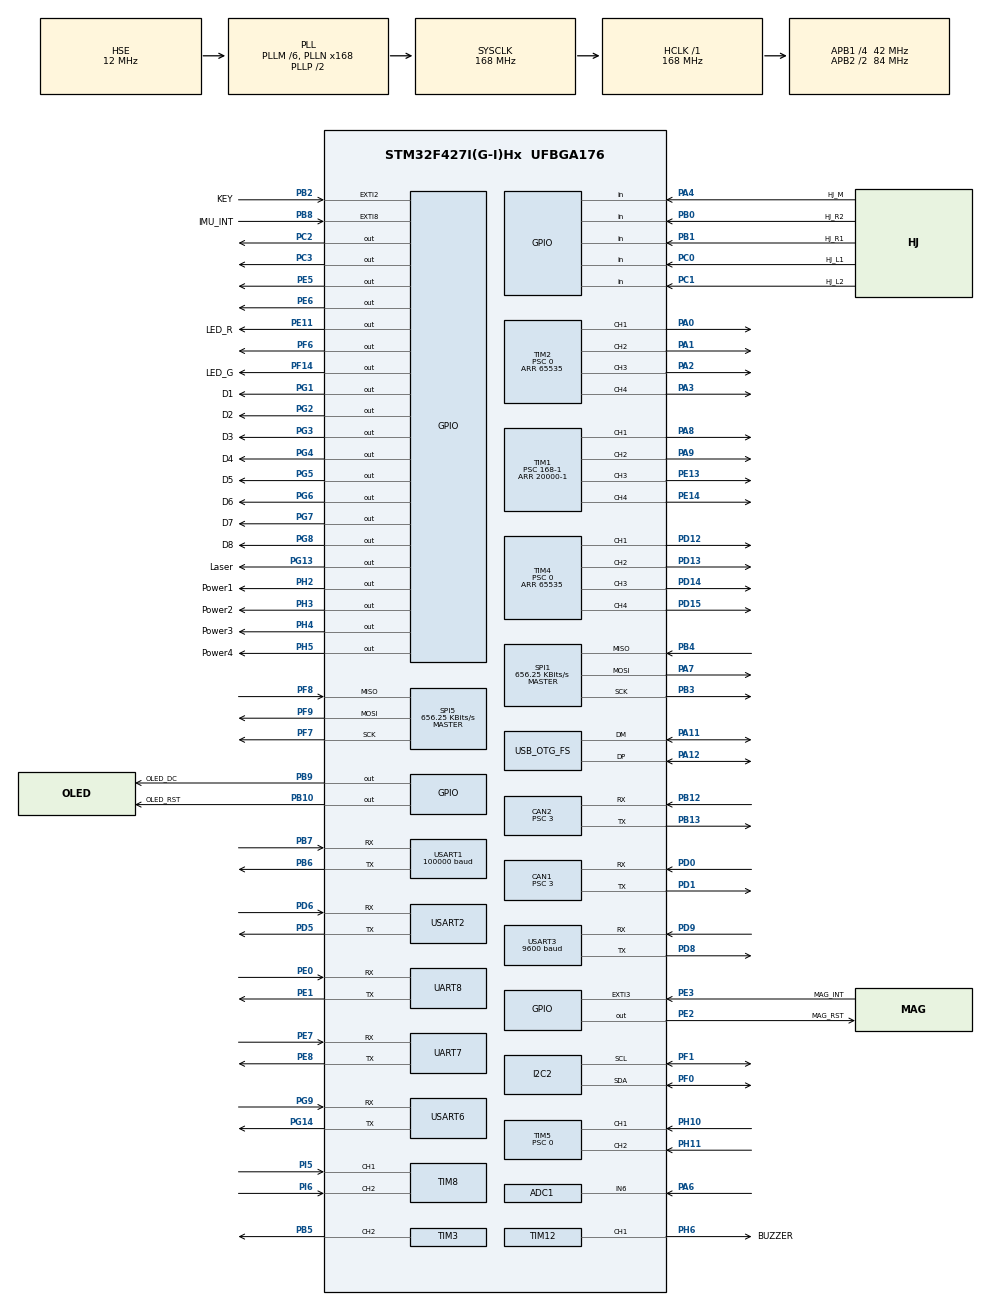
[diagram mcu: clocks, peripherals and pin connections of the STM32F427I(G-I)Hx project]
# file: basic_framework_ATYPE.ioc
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ADC1.Channel-0\#ChannelRegularConversion=ADC_CHANNEL_6
ADC1.NbrOfConversionFlag=1
ADC1.Rank-0\#ChannelRegularConversion=1
ADC1.SamplingTime-0\#ChannelRegularConversion=ADC_SAMPLETIME_3CYCLES
ADC1.master=1
CAN1.BS1=CAN_BS1_10TQ
CAN1.BS2=CAN_BS2_3TQ
CAN1.CalculateBaudRate=1000000
CAN1.CalculateTimeBit=1000
CAN1.CalculateTimeQuantum=71.42857142857143
CAN1.ABOM=ENABLE
CAN1.NART=ENABLE
CAN1.Prescaler=3
CAN1.TXFP=ENABLE
CAN2.BS1=CAN_BS1_10TQ
CAN2.BS2=CAN_BS2_3TQ
CAN2.CalculateBaudRate=1000000
CAN2.CalculateTimeBit=1000
CAN2.CalculateTimeQuantum=71.42857142857143
CAN2.ABOM=ENABLE
CAN2.NART=ENABLE
CAN2.Prescaler=3
CAN2.TXFP=ENABLE
Dma.Request0=USART1_RX
Dma.Request1=USART3_RX
Dma.Request2=USART3_TX
Dma.Request3=USART6_RX
Dma.Request4=USART6_TX
Dma.Request5=UART7_RX
Dma.Request6=UART8_RX
Dma.Request7=UART8_TX
Dma.Request8=USART2_RX
Dma.UART7_RX.5.Direction=DMA_PERIPH_TO_MEMORY
Dma.UART7_RX.5.FIFOMode=DMA_FIFOMODE_ENABLE
Dma.UART7_RX.5.FIFOThreshold=DMA_FIFO_THRESHOLD_FULL
Dma.UART7_RX.5.Instance=DMA1_Stream3
Dma.UART7_RX.5.MemBurst=DMA_MBURST_SINGLE
Dma.UART7_RX.5.MemDataAlignment=DMA_MDATAALIGN_BYTE
Dma.UART7_RX.5.MemInc=DMA_MINC_ENABLE
Dma.UART7_RX.5.Mode=DMA_NORMAL
Dma.UART7_RX.5.PeriphBurst=DMA_PBURST_SINGLE
Dma.UART7_RX.5.PeriphDataAlignment=DMA_PDATAALIGN_BYTE
Dma.UART7_RX.5.PeriphInc=DMA_PINC_DISABLE
Dma.UART7_RX.5.Priority=DMA_PRIORITY_LOW
Dma.UART8_RX.6.Direction=DMA_PERIPH_TO_MEMORY
Dma.UART8_RX.6.FIFOMode=DMA_FIFOMODE_ENABLE
Dma.UART8_RX.6.FIFOThreshold=DMA_FIFO_THRESHOLD_FULL
Dma.UART8_RX.6.Instance=DMA1_Stream6
Dma.UART8_RX.6.MemBurst=DMA_MBURST_SINGLE
Dma.UART8_RX.6.MemDataAlignment=DMA_MDATAALIGN_BYTE
Dma.UART8_RX.6.MemInc=DMA_MINC_ENABLE
Dma.UART8_RX.6.Mode=DMA_NORMAL
Dma.UART8_RX.6.PeriphBurst=DMA_PBURST_SINGLE
Dma.UART8_RX.6.PeriphDataAlignment=DMA_PDATAALIGN_BYTE
Dma.UART8_RX.6.PeriphInc=DMA_PINC_DISABLE
Dma.UART8_RX.6.Priority=DMA_PRIORITY_LOW
Dma.UART8_TX.7.Direction=DMA_MEMORY_TO_PERIPH
Dma.UART8_TX.7.FIFOMode=DMA_FIFOMODE_DISABLE
Dma.UART8_TX.7.Instance=DMA1_Stream0
Dma.UART8_TX.7.MemDataAlignment=DMA_MDATAALIGN_BYTE
Dma.UART8_TX.7.MemInc=DMA_MINC_ENABLE
Dma.UART8_TX.7.Mode=DMA_NORMAL
Dma.UART8_TX.7.PeriphDataAlignment=DMA_PDATAALIGN_BYTE
Dma.UART8_TX.7.PeriphInc=DMA_PINC_DISABLE
Dma.UART8_TX.7.Priority=DMA_PRIORITY_LOW
Dma.USART1_RX.0.Direction=DMA_PERIPH_TO_MEMORY
Dma.USART1_RX.0.FIFOMode=DMA_FIFOMODE_DISABLE
Dma.USART1_RX.0.Instance=DMA2_Stream2
Dma.USART1_RX.0.MemDataAlignment=DMA_MDATAALIGN_BYTE
Dma.USART1_RX.0.MemInc=DMA_MINC_ENABLE
Dma.USART1_RX.0.Mode=DMA_NORMAL
Dma.USART1_RX.0.PeriphDataAlignment=DMA_PDATAALIGN_BYTE
Dma.USART1_RX.0.PeriphInc=DMA_PINC_DISABLE
Dma.USART1_RX.0.Priority=DMA_PRIORITY_LOW
Dma.USART2_RX.8.Direction=DMA_PERIPH_TO_MEMORY
Dma.USART2_RX.8.FIFOMode=DMA_FIFOMODE_DISABLE
Dma.USART2_RX.8.Instance=DMA1_Stream5
Dma.USART2_RX.8.MemDataAlignment=DMA_MDATAALIGN_BYTE
Dma.USART2_RX.8.MemInc=DMA_MINC_ENABLE
Dma.USART2_RX.8.Mode=DMA_NORMAL
Dma.USART2_RX.8.PeriphDataAlignment=DMA_PDATAALIGN_BYTE
Dma.USART2_RX.8.PeriphInc=DMA_PINC_DISABLE
Dma.USART2_RX.8.Priority=DMA_PRIORITY_HIGH
Dma.USART3_RX.1.Direction=DMA_PERIPH_TO_MEMORY
Dma.USART3_RX.1.FIFOMode=DMA_FIFOMODE_DISABLE
Dma.USART3_RX.1.Instance=DMA1_Stream1
Dma.USART3_RX.1.MemDataAlignment=DMA_MDATAALIGN_BYTE
Dma.USART3_RX.1.MemInc=DMA_MINC_ENABLE
Dma.USART3_RX.1.Mode=DMA_NORMAL
Dma.USART3_RX.1.PeriphDataAlignment=DMA_PDATAALIGN_BYTE
Dma.USART3_RX.1.PeriphInc=DMA_PINC_DISABLE
Dma.USART3_RX.1.Priority=DMA_PRIORITY_VERY_HIGH
Dma.USART3_TX.2.Direction=DMA_MEMORY_TO_PERIPH
Dma.USART3_TX.2.FIFOMode=DMA_FIFOMODE_DISABLE
Dma.USART3_TX.2.Instance=DMA1_Stream4
Dma.USART3_TX.2.MemDataAlignment=DMA_MDATAALIGN_BYTE
Dma.USART3_TX.2.MemInc=DMA_MINC_ENABLE
Dma.USART3_TX.2.Mode=DMA_NORMAL
Dma.USART3_TX.2.PeriphDataAlignment=DMA_PDATAALIGN_BYTE
Dma.USART3_TX.2.PeriphInc=DMA_PINC_DISABLE
Dma.USART3_TX.2.Priority=DMA_PRIORITY_VERY_HIGH
Dma.USART6_RX.3.Direction=DMA_PERIPH_TO_MEMORY
Dma.USART6_RX.3.FIFOMode=DMA_FIFOMODE_DISABLE
Dma.USART6_RX.3.Instance=DMA2_Stream1
Dma.USART6_RX.3.MemDataAlignment=DMA_MDATAALIGN_BYTE
Dma.USART6_RX.3.MemInc=DMA_MINC_ENABLE
Dma.USART6_RX.3.Mode=DMA_NORMAL
Dma.USART6_RX.3.PeriphDataAlignment=DMA_PDATAALIGN_BYTE
Dma.USART6_RX.3.PeriphInc=DMA_PINC_DISABLE
Dma.USART6_RX.3.Priority=DMA_PRIORITY_HIGH
Dma.USART6_TX.4.Direction=DMA_MEMORY_TO_PERIPH
Dma.USART6_TX.4.FIFOMode=DMA_FIFOMODE_DISABLE
Dma.USART6_TX.4.Instance=DMA2_Stream6
Dma.USART6_TX.4.MemDataAlignment=DMA_MDATAALIGN_BYTE
Dma.USART6_TX.4.MemInc=DMA_MINC_ENABLE
Dma.USART6_TX.4.Mode=DMA_NORMAL
Dma.USART6_TX.4.PeriphDataAlignment=DMA_PDATAALIGN_BYTE
Dma.USART6_TX.4.PeriphInc=DMA_PINC_DISABLE
Dma.USART6_TX.4.Priority=DMA_PRIORITY_HIGH
FREERTOS.INCLUDE_vTaskDelayUntil=1
FREERTOS.Tasks01=defaultTask,0,128,StartDefaultTask,Default,NULL,Dynamic,NULL,NULL
FREERTOS.configENABLE_FPU=1
FREERTOS.configMAX_TASK_NAME_LEN=32
FREERTOS.configTOTAL_HEAP_SIZE=30000
Mcu.Family=STM32F4
Mcu.Name=STM32F427I(G-I)Hx
Mcu.Package=UFBGA176
NVIC.CAN1_RX0_IRQn=true\:5\:0\:false\:false\:true\:true\:true\:true\:true
NVIC.CAN1_RX1_IRQn=true\:5\:0\:false\:false\:true\:true\:true\:true\:true
NVIC.CAN2_RX0_IRQn=true\:5\:0\:false\:false\:true\:true\:true\:true\:true
NVIC.CAN2_RX1_IRQn=true\:5\:0\:false\:false\:true\:true\:true\:true\:true
NVIC.DMA1_Stream0_IRQn=true\:5\:0\:false\:false\:true\:true\:false\:true\:true
NVIC.DMA1_Stream1_IRQn=true\:5\:0\:false\:false\:true\:true\:false\:true\:true
NVIC.DMA1_Stream3_IRQn=true\:5\:0\:false\:false\:true\:true\:false\:true\:true
NVIC.DMA1_Stream4_IRQn=true\:5\:0\:false\:false\:true\:false\:false\:true\:true
NVIC.DMA1_Stream5_IRQn=true\:5\:0\:false\:false\:true\:true\:false\:true\:true
NVIC.DMA1_Stream6_IRQn=true\:5\:0\:false\:false\:true\:true\:false\:true\:true
NVIC.DMA2_Stream1_IRQn=true\:5\:0\:false\:false\:true\:true\:false\:true\:true
NVIC.DMA2_Stream2_IRQn=true\:5\:0\:false\:false\:true\:true\:false\:true\:true
NVIC.DMA2_Stream6_IRQn=true\:5\:0\:false\:false\:true\:true\:false\:true\:true
NVIC.EXTI2_IRQn=true\:5\:0\:false\:false\:true\:true\:true\:true\:true
NVIC.OTG_FS_IRQn=true\:5\:0\:false\:false\:true\:true\:false\:true\:true
NVIC.PriorityGroup=NVIC_PRIORITYGROUP_4
NVIC.SPI5_IRQn=true\:5\:0\:false\:false\:true\:true\:true\:true\:true
NVIC.TIM8_TRG_COM_TIM14_IRQn=true\:15\:0\:false\:false\:true\:false\:false\:true\:true
NVIC.TimeBase=TIM8_TRG_COM_TIM14_IRQn
NVIC.TimeBaseIP=TIM14
NVIC.UART7_IRQn=true\:5\:0\:false\:false\:true\:true\:true\:true\:true
NVIC.UART8_IRQn=true\:5\:0\:false\:false\:true\:true\:true\:true\:true
NVIC.USART1_IRQn=true\:5\:0\:false\:false\:true\:true\:true\:true\:true
NVIC.USART2_IRQn=true\:5\:0\:false\:false\:true\:true\:true\:true\:true
NVIC.USART3_IRQn=true\:5\:0\:false\:false\:true\:true\:true\:true\:true
NVIC.USART6_IRQn=true\:5\:0\:false\:false\:true\:true\:true\:true\:true
PA0/WKUP.Signal=S_TIM2_CH1_ETR
PA1.Signal=S_TIM2_CH2
PA10.Signal=USB_OTG_FS_ID
PA11.Mode=Device_Only
PA11.Signal=USB_OTG_FS_DM
PA12.Mode=Device_Only
PA12.Signal=USB_OTG_FS_DP
PA13.Mode=Serial_Wire
PA13.Signal=SYS_JTMS-SWDIO
PA14.Mode=Serial_Wire
PA14.Signal=SYS_JTCK-SWCLK
PA2.Signal=S_TIM2_CH3
PA3.Signal=S_TIM2_CH4
PA4.GPIO_Label=HJ_M
PA4.Signal=GPIO_Input
PA6.Signal=ADCx_IN6
PA7.Mode=Full_Duplex_Master
PA7.Signal=SPI1_MOSI
PA8.Signal=S_TIM1_CH1
PA9.Signal=S_TIM1_CH2
PB0.GPIO_Label=HJ_R2
PB0.Signal=GPIO_Input
PB1.GPIO_Label=HJ_R1
PB1.Signal=GPIO_Input
PB10.GPIO_Label=OLED_RST
PB10.Signal=GPIO_Output
PB12.Mode=CAN_Activate
PB12.Signal=CAN2_RX
PB13.Mode=CAN_Activate
PB13.Signal=CAN2_TX
PB2/BOOT1.GPIO_Label=KEY
PB2/BOOT1.GPIO_ModeDefaultEXTI=GPIO_MODE_IT_RISING
PB2/BOOT1.GPIO_PuPd=GPIO_PULLDOWN
PB2/BOOT1.Signal=GPXTI2
PB3.Mode=Full_Duplex_Master
PB3.Signal=SPI1_SCK
PB4.Mode=Full_Duplex_Master
PB4.Signal=SPI1_MISO
PB5.Signal=S_TIM3_CH2
PB6.Mode=Asynchronous
PB6.Signal=USART1_TX
PB7.Mode=Asynchronous
PB7.Signal=USART1_RX
PB8.GPIO_Label=IMU_INT
PB8.Signal=GPXTI8
PB9.GPIO_Label=OLED_DC
PB9.Signal=GPIO_Output
PC0.GPIO_Label=HJ_L1
PC0.Signal=GPIO_Input
PC1.GPIO_Label=HJ_L2
PC1.GPIO_PuPd=GPIO_NOPULL
PC1.Signal=GPIO_Input
PC2.GPIO_Speed=GPIO_SPEED_FREQ_HIGH
PC2.Signal=GPIO_Output
PC3.GPIO_Speed=GPIO_SPEED_FREQ_HIGH
PC3.Signal=GPIO_Output
PD0.Mode=CAN_Activate
PD0.Signal=CAN1_RX
PD1.Mode=CAN_Activate
PD1.Signal=CAN1_TX
PD12.Signal=S_TIM4_CH1
PD13.Signal=S_TIM4_CH2
PD14.Signal=S_TIM4_CH3
PD15.Signal=S_TIM4_CH4
PD5.Mode=Asynchronous
PD5.Signal=USART2_TX
PD6.Mode=Asynchronous
PD6.Signal=USART2_RX
PD8.Mode=Asynchronous
PD8.Signal=USART3_TX
PD9.Mode=Asynchronous
PD9.Signal=USART3_RX
PE0.Mode=Asynchronous
PE0.Signal=UART8_RX
PE1.Mode=Asynchronous
PE1.Signal=UART8_TX
PE11.GPIO_Label=LED_R
PE11.Signal=GPIO_Output
PE13.Signal=S_TIM1_CH3
PE14.Signal=S_TIM1_CH4
PE2.GPIO_Label=MAG_RST
PE2.Signal=GPIO_Output
PE3.GPIO_Label=MAG_INT
PE3.Signal=GPXTI3
PE5.GPIO_Speed=GPIO_SPEED_FREQ_HIGH
PE5.Signal=GPIO_Output
PE6.GPIO_Speed=GPIO_SPEED_FREQ_HIGH
PE6.Signal=GPIO_Output
PE7.Mode=Asynchronous
PE7.Signal=UART7_RX
PE8.Mode=Asynchronous
PE8.Signal=UART7_TX
PF0.Mode=I2C
PF0.Signal=I2C2_SDA
PF1.Mode=I2C
PF1.Signal=I2C2_SCL
PF14.GPIO_Label=LED_G
PF14.Signal=GPIO_Output
PF6.Signal=GPIO_Output
PF7.Mode=Full_Duplex_Master
PF7.Signal=SPI5_SCK
PF8.Mode=Full_Duplex_Master
PF8.Signal=SPI5_MISO
PF9.Mode=Full_Duplex_Master
PF9.Signal=SPI5_MOSI
PG1.GPIO_Label=D1
PG1.Signal=GPIO_Output
PG13.GPIO_Label=Laser
PG13.GPIO_PuPd=GPIO_PULLUP
PG13.Signal=GPIO_Output
PG14.Mode=Asynchronous
PG14.Signal=USART6_TX
PG2.GPIO_Label=D2
PG2.Signal=GPIO_Output
PG3.GPIO_Label=D3
PG3.Signal=GPIO_Output
PG4.GPIO_Label=D4
PG4.Signal=GPIO_Output
PG5.GPIO_Label=D5
PG5.Signal=GPIO_Output
PG6.GPIO_Label=D6
PG6.Signal=GPIO_Output
PG7.GPIO_Label=D7
PG7.Signal=GPIO_Output
PG8.GPIO_Label=D8
PG8.Signal=GPIO_Output
PG9.Mode=Asynchronous
PG9.Signal=USART6_RX
PH0/OSC_IN.Mode=HSE-External-Oscillator
PH0/OSC_IN.Signal=RCC_OSC_IN
PH1/OSC_OUT.Mode=HSE-External-Oscillator
PH1/OSC_OUT.Signal=RCC_OSC_OUT
PH10.Signal=S_TIM5_CH1
PH11.Signal=S_TIM5_CH2
PH2.GPIO_Label=Power1
PH2.GPIO_PuPd=GPIO_PULLDOWN
PH2.Signal=GPIO_Output
PH3.GPIO_Label=Power2
PH3.GPIO_PuPd=GPIO_PULLDOWN
PH3.Signal=GPIO_Output
PH4.GPIO_Label=Power3
PH4.GPIO_PuPd=GPIO_PULLDOWN
PH4.Signal=GPIO_Output
PH5.GPIO_Label=Power4
PH5.GPIO_PuPd=GPIO_PULLDOWN
PH5.Signal=GPIO_Output
PH6.GPIO_Label=BUZZER
PH6.GPIO_PuPd=GPIO_PULLUP
PH6.GPIO_Speed=GPIO_SPEED_FREQ_VERY_HIGH
PH6.Signal=S_TIM12_CH1
PI5.Signal=S_TIM8_CH1
PI6.Signal=S_TIM8_CH2
ProjectManager.HeapSize=0x4000
ProjectManager.StackSize=0x4000
ProjectManager.TargetToolchain=CMake
RCC.48MHZClocksFreq_Value=48000000
RCC.AHBFreq_Value=168000000
RCC.APB1CLKDivider=RCC_HCLK_DIV4
RCC.APB1Freq_Value=42000000
RCC.APB1TimFreq_Value=84000000
RCC.APB2CLKDivider=RCC_HCLK_DIV2
RCC.APB2Freq_Value=84000000
RCC.APB2TimFreq_Value=168000000
RCC.CortexFreq_Value=168000000
RCC.HCLKFreq_Value=168000000
RCC.HSE_VALUE=12000000
RCC.HSI_VALUE=16000000
RCC.LSE_VALUE=32768
RCC.PLLM=6
RCC.PLLN=168
RCC.PLLQ=7
RCC.SYSCLKFreq_VALUE=168000000
RCC.SYSCLKSource=RCC_SYSCLKSOURCE_PLLCLK
RCC.VCOOutputFreq_Value=336000000
RTC.AsynchPrediv=124
RTC.SynchPrediv=3199
SH.ADCx_IN6.0=ADC1_IN6,IN6
SH.S_TIM12_CH1.0=TIM12_CH1,PWM Generation1 CH1
SH.S_TIM1_CH1.0=TIM1_CH1,PWM Generation1 CH1
SH.S_TIM1_CH2.0=TIM1_CH2,PWM Generation2 CH2
SH.S_TIM1_CH3.0=TIM1_CH3,PWM Generation3 CH3
SH.S_TIM1_CH4.0=TIM1_CH4,PWM Generation4 CH4
SH.S_TIM2_CH1_ETR.0=TIM2_CH1,PWM Generation1 CH1
SH.S_TIM2_CH2.0=TIM2_CH2,PWM Generation2 CH2
SH.S_TIM2_CH3.0=TIM2_CH3,PWM Generation3 CH3
SH.S_TIM2_CH4.0=TIM2_CH4,PWM Generation4 CH4
SH.S_TIM3_CH2.0=TIM3_CH2,PWM Generation2 CH2
SH.S_TIM4_CH1.0=TIM4_CH1,PWM Generation1 CH1
SH.S_TIM4_CH2.0=TIM4_CH2,PWM Generation2 CH2
SH.S_TIM4_CH3.0=TIM4_CH3,PWM Generation3 CH3
SH.S_TIM4_CH4.0=TIM4_CH4,PWM Generation4 CH4
SH.S_TIM5_CH1.0=TIM5_CH1,Encoder_Interface
SH.S_TIM5_CH2.0=TIM5_CH2,Encoder_Interface
SH.S_TIM8_CH1.0=TIM8_CH1,Encoder_Interface
SH.S_TIM8_CH2.0=TIM8_CH2,Encoder_Interface
SPI1.BaudRatePrescaler=SPI_BAUDRATEPRESCALER_128
SPI1.CalculateBaudRate=656.25 KBits/s
SPI1.Direction=SPI_DIRECTION_2LINES
SPI1.Mode=SPI_MODE_MASTER
SPI1.VirtualType=VM_MASTER
SPI5.BaudRatePrescaler=SPI_BAUDRATEPRESCALER_128
SPI5.CLKPhase=SPI_PHASE_2EDGE
SPI5.CLKPolarity=SPI_POLARITY_HIGH
SPI5.CalculateBaudRate=656.25 KBits/s
SPI5.Direction=SPI_DIRECTION_2LINES
SPI5.Mode=SPI_MODE_MASTER
SPI5.VirtualType=VM_MASTER
STMicroelectronics.X-CUBE-ALGOBUILD.1.3.0.LibraryCcDSPOoLibraryJjDSPOoLibrary=true
TIM1.Channel-PWM\ Generation1\ CH1=TIM_CHANNEL_1
TIM1.Channel-PWM\ Generation2\ CH2=TIM_CHANNEL_2
TIM1.Channel-PWM\ Generation3\ CH3=TIM_CHANNEL_3
TIM1.Channel-PWM\ Generation4\ CH4=TIM_CHANNEL_4
TIM1.Period=20000-1
TIM1.Prescaler=168-1
TIM1.Pulse-PWM\ Generation1\ CH1=2000
TIM1.Pulse-PWM\ Generation2\ CH2=2000
TIM1.Pulse-PWM\ Generation3\ CH3=2000
TIM1.Pulse-PWM\ Generation4\ CH4=2000
TIM12.Channel-PWM\ Generation1\ CH1=TIM_CHANNEL_1
TIM12.Period=10000-1
TIM12.Prescaler=84-1
TIM12.Pulse-PWM\ Generation1\ CH1=2000
TIM2.Channel-PWM\ Generation1\ CH1=TIM_CHANNEL_1
TIM2.Channel-PWM\ Generation2\ CH2=TIM_CHANNEL_2
TIM2.Channel-PWM\ Generation3\ CH3=TIM_CHANNEL_3
TIM2.Channel-PWM\ Generation4\ CH4=TIM_CHANNEL_4
TIM2.Period=65535
TIM2.Prescaler=0
TIM2.Pulse-PWM\ Generation1\ CH1=2000
TIM2.Pulse-PWM\ Generation2\ CH2=2000
TIM2.Pulse-PWM\ Generation3\ CH3=2000
TIM2.Pulse-PWM\ Generation4\ CH4=2000
TIM3.Channel-PWM\ Generation2\ CH2=TIM_CHANNEL_2
TIM3.Period=10000-1
TIM3.Prescaler=84-1
TIM3.Pulse-PWM\ Generation2\ CH2=2000
TIM4.Channel-PWM\ Generation1\ CH1=TIM_CHANNEL_1
TIM4.Channel-PWM\ Generation2\ CH2=TIM_CHANNEL_2
TIM4.Channel-PWM\ Generation3\ CH3=TIM_CHANNEL_3
TIM4.Channel-PWM\ Generation4\ CH4=TIM_CHANNEL_4
TIM4.Period=65535
TIM4.Prescaler=0
TIM4.Pulse-PWM\ Generation1\ CH1=2000
TIM4.Pulse-PWM\ Generation2\ CH2=2000
TIM4.Pulse-PWM\ Generation3\ CH3=2000
TIM4.Pulse-PWM\ Generation4\ CH4=2000
TIM5.EncoderMode=TIM_ENCODERMODE_TI12
TIM5.Period=4294967295
TIM5.Prescaler=0
TIM8.EncoderMode=TIM_ENCODERMODE_TI12
TIM8.IC1Filter=10
TIM8.IC2Filter=10
UART7.VirtualMode=Asynchronous
UART8.VirtualMode=Asynchronous
USART1.BaudRate=100000
USART1.Parity=PARITY_EVEN
USART1.VirtualMode=VM_ASYNC
USART1.WordLength=WORDLENGTH_9B
USART2.VirtualMode=VM_ASYNC
USART3.BaudRate=9600
USART3.VirtualMode=VM_ASYNC
USART6.VirtualMode=VM_ASYNC
USB_DEVICE.CLASS_NAME_FS=CDC
USB_DEVICE.MANUFACTURER_STRING-CDC_FS=YueLuEmbedded
USB_DEVICE.PID_CDC_FS=202
USB_DEVICE.PRODUCT_STRING_CDC_FS=Motor Bench CDC
USB_DEVICE.VirtualMode-CDC_FS=Cdc
USB_DEVICE.VirtualModeFS=Cdc_FS
USB_OTG_FS.VirtualMode=Device_Only
VP_CRC_VS_CRC.Mode=CRC_Activate
VP_FREERTOS_VS_CMSIS_V1.Mode=CMSIS_V1
VP_RNG_VS_RNG.Mode=RNG_Activate
VP_RTC_VS_RTC_Activate.Mode=RTC_Enabled
VP_STMicroelectronics.X-CUBE-ALGOBUILD_VS_DSPOoLibraryJjLibrary_1.3.0_1.3.0.Mode=DSPOoLibraryJjLibrary
VP_SYS_VS_tim14.Mode=TIM14
VP_TIM12_VS_ClockSourceINT.Mode=Internal
VP_TIM1_VS_ClockSourceINT.Mode=Internal
VP_TIM2_VS_ClockSourceINT.Mode=Internal
VP_TIM3_VS_ClockSourceINT.Mode=Internal
VP_TIM4_VS_ClockSourceINT.Mode=Internal
VP_USB_DEVICE_VS_USB_DEVICE_CDC_FS.Mode=CDC_FS
board=custom

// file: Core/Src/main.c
/* USER CODE BEGIN Header */
/**
  ******************************************************************************
  * @file           : main.c
  * @brief          : Main program body
  ******************************************************************************
  * @attention
  *
  * Copyright (c) 2026 STMicroelectronics.
  * All rights reserved.
  *
  * This software is licensed under terms that can be found in the LICENSE file
  * in the root directory of this software component.
  * If no LICENSE file comes with this software, it is provided AS-IS.
  *
  ******************************************************************************
  */
/* USER CODE END Header */
#include "main.h"
#include "cmsis_os.h"
#include "adc.h"
#include "can.h"
#include "crc.h"
#include "dma.h"
#include "i2c.h"
#include "rng.h"
#include "rtc.h"
#include "spi.h"
#include "tim.h"
#include "usart.h"
#include "usb_device.h"
#include "gpio.h"

/* USER CODE BEGIN Includes */
#include "robot.h"
#include "SEGGER_RTT.h"
/* USER CODE END Includes */

void SystemClock_Config(void);
void MX_FREERTOS_Init(void);

int main(void)
{
  /* USER CODE BEGIN 1 */
  SEGGER_RTT_Init();
  SEGGER_RTT_WriteString(0, "\r\n[P] === main() entered ===\r\n");
/* USER CODE END 1 */

  /* MCU Configuration--------------------------------------------------------*/

  /* Reset of all peripherals, Initializes the Flash interface and the Systick. */
  HAL_Init();

  /* Configure the system clock */
  SystemClock_Config();

  /* Initialize all configured peripherals */
  MX_GPIO_Init();
  MX_DMA_Init();
  MX_RTC_Init();
  MX_TIM1_Init();
  MX_CAN1_Init();
  MX_CAN2_Init();
  MX_TIM2_Init();
  MX_TIM4_Init();
  MX_TIM5_Init();
  MX_TIM8_Init();
  MX_USART1_UART_Init();
  MX_USART3_UART_Init();
  MX_USART6_UART_Init();
  MX_CRC_Init();
  MX_RNG_Init();
  MX_TIM12_Init();
  MX_UART7_Init();
  MX_UART8_Init();
  MX_SPI5_Init();
  MX_TIM3_Init();
  MX_I2C2_Init();
  MX_SPI1_Init();
  MX_ADC1_Init();
  MX_USART2_UART_Init();
  /* USER CODE BEGIN 2 */
  /* DWT and the bench callbacks must be ready before USB enumeration. */
  RobotInit();
/* USER CODE END 2 */

  /* Call init function for freertos objects (in freertos.c) */
  MX_FREERTOS_Init();

  /* Start scheduler */
  osKernelStart();

  /* We should never get here as control is now taken by the scheduler */
  /* Infinite loop */
  while (1)
  {

  }
}

void SystemClock_Config(void)
{
  RCC_OscInitTypeDef RCC_OscInitStruct = {0};
  RCC_ClkInitTypeDef RCC_ClkInitStruct = {0};

  /** Configure the main internal regulator output voltage
  */
  __HAL_RCC_PWR_CLK_ENABLE();
  __HAL_PWR_VOLTAGESCALING_CONFIG(PWR_REGULATOR_VOLTAGE_SCALE1);

  /** Initializes the RCC Oscillators according to the specified parameters
  * in the RCC_OscInitTypeDef structure.
  */
  RCC_OscInitStruct.OscillatorType = RCC_OSCILLATORTYPE_LSI|RCC_OSCILLATORTYPE_HSE;
  RCC_OscInitStruct.HSEState = RCC_HSE_ON;
  RCC_OscInitStruct.LSIState = RCC_LSI_ON;
  RCC_OscInitStruct.PLL.PLLState = RCC_PLL_ON;
  RCC_OscInitStruct.PLL.PLLSource = RCC_PLLSOURCE_HSE;
  RCC_OscInitStruct.PLL.PLLM = 6;
  RCC_OscInitStruct.PLL.PLLN = 168;
  RCC_OscInitStruct.PLL.PLLP = RCC_PLLP_DIV2;
  RCC_OscInitStruct.PLL.PLLQ = 7;
  if (HAL_RCC_OscConfig(&RCC_OscInitStruct) != HAL_OK)
  {
    Error_Handler();
  }

  /** Initializes the CPU, AHB and APB buses clocks
  */
  RCC_ClkInitStruct.ClockType = RCC_CLOCKTYPE_HCLK|RCC_CLOCKTYPE_SYSCLK
                              |RCC_CLOCKTYPE_PCLK1|RCC_CLOCKTYPE_PCLK2;
  RCC_ClkInitStruct.SYSCLKSource = RCC_SYSCLKSOURCE_PLLCLK;
  RCC_ClkInitStruct.AHBCLKDivider = RCC_SYSCLK_DIV1;
  RCC_ClkInitStruct.APB1CLKDivider = RCC_HCLK_DIV4;
  RCC_ClkInitStruct.APB2CLKDivider = RCC_HCLK_DIV2;

  if (HAL_RCC_ClockConfig(&RCC_ClkInitStruct, FLASH_LATENCY_5) != HAL_OK)
  {
    Error_Handler();
  }
}

void HAL_TIM_PeriodElapsedCallback(TIM_HandleTypeDef *htim)
{
  if (htim->Instance == TIM14) {
    HAL_IncTick();
  }
}

void Error_Handler(void)
{
  __disable_irq();
  while (1)
  {
  }
}
